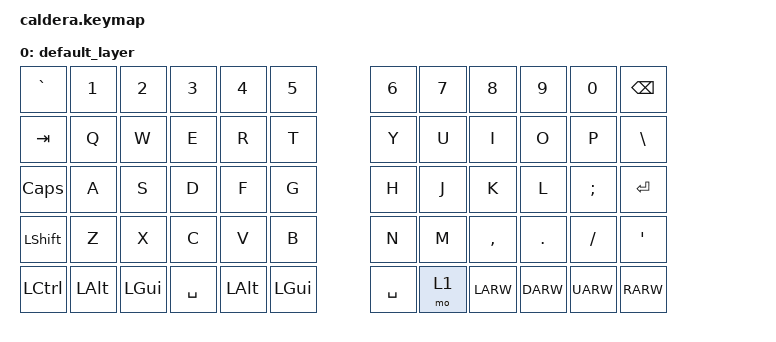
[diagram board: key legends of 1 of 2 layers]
#include <behaviors.dtsi>
#include <dt-bindings/zmk/keys.h>
#include <dt-bindings/zmk/bt.h>

/ {
    macros {
        AE: AE {
            compatible = "zmk,behavior-macro";
            #binding-cells = <0>;
            bindings
                = <&macro_press &kp RALT>
                , <&macro_tap &kp Q>
                , <&macro_release &kp RALT>
                ;
        };
        OE: OE {
            compatible = "zmk,behavior-macro";
            #binding-cells = <0>;
            bindings
                = <&macro_press &kp RALT>
                , <&macro_tap &kp P>
                , <&macro_release &kp RALT>
                ;
        };
        UE: UE {
            compatible = "zmk,behavior-macro";
            #binding-cells = <0>;
            bindings
                = <&macro_press &kp RALT>
                , <&macro_tap &kp Y>
                , <&macro_release &kp RALT>
                ;
        };
        SZ: SZ {
            compatible = "zmk,behavior-macro";
            #binding-cells = <0>;
            bindings
                = <&macro_press &kp RALT>
                , <&macro_tap &kp S>
                , <&macro_release &kp RALT>
                ;
        };
    };
};

/ {
        keymap {
                compatible = "zmk,keymap";

                default_layer {
// ---------------------------------------------------------------------------------
// |   `  |  1  |  2  |  3  |  4  |  5  |     |  6  |  7  |  8  |  9  |  0  | BKSP |
// |  TAB |  Q  |  W  |  E  |  R  |  T  |     |  Y  |  U  |  I  |  O  |  P  |  \   |
// | CAPS |  A  |  S  |  D  |  F  |  G  |     |  H  |  J  |  K  |  L  |  ;  |  ENT |
// | SHFT |  Z  |  X  |  C  |  V  |  B  |     |  N  |  M  |  ,  |  .  |  /  | APOS |
// | CTRL | ALT | GUI | SPC | SPC | SPC |     | SPC | LOW |LARW |DARW |UARW | RARW |
                        bindings = <
   &kp GRAVE  &kp N1    &kp N2    &kp N3     &kp N4     &kp N5               &kp N6     &kp N7  &kp N8     &kp N9    &kp N0    &kp BSPC
   &kp TAB    &kp Q     &kp W     &kp E      &kp R      &kp T                &kp Y      &kp U   &kp I      &kp O     &kp P     &kp BSLH
   &kp CAPS   &kp A     &kp S     &kp D      &kp F      &kp G                &kp H      &kp J   &kp K      &kp L     &kp SEMI  &kp RET
   &kp LSHFT  &kp Z     &kp X     &kp C      &kp V      &kp B                &kp N      &kp M   &kp COMMA  &kp DOT   &kp FSLH  &kp APOS
   &kp LCTRL  &kp LALT  &kp LGUI  &kp SPACE  &kp LALT   &kp LGUI             &kp SPACE  &mo 1   &kp LARW   &kp DARW  &kp UARW  &kp RARW
                        >;
                };
                lower_layer {
// ------------------------------------------------------------------------------------------------------------
// |       |  BT1  |  BT2  |  BT3  |  BT4  |  BT5  |          |       |       |       |       |       | BTCLR |
// |       |       |       |       |       |       |          |   Ü   |       |   Ö   |       |       |       |
// |       |   Ä   |   ß   | LPAR  | RPAR  |       |          |       | LBKT  | RBKT  |       |       |       |
// |       |       |       |       |       |       |          |       |       |       |       |       |       |
                        bindings = <
   &trans    &bt BT_SEL 0   &bt BT_SEL 1   &bt BT_SEL 2   &bt BT_SEL 3   &bt BT_SEL 4           &trans    &trans    &trans   &trans   &trans  &bt BT_CLR
   &trans    &trans         &trans         &trans         &trans         &trans                 &trans    &UE       &trans   &OE      &trans  &trans
   &trans    &AE            &SZ            &kp LPAR       &kp RPAR       &trans                 &trans    &kp LBKT  &kp RBKT &kp MINUS   &kp EQUAL  &trans
   &trans    &trans         &trans         &trans         &trans         &trans                 &trans    &trans    &trans   &trans   &trans  &trans
                        >;
                };
        };
};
